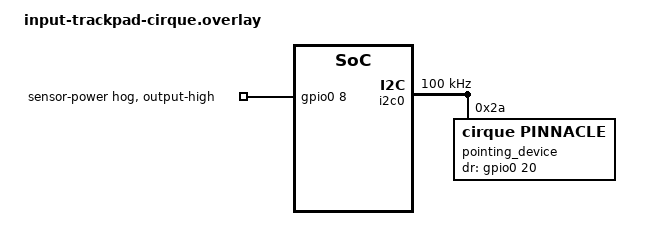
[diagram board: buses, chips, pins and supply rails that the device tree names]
/*
 * Cirque TM040040 (Pinnacle 1CA027) on the 6-pin sensor connector, in I2C
 * mode, replacing the trackball. Use instead of input-trackball.
 *
 * Connector  MCU    Function     TM040040 pad (FFC pin)
 *   1        GND    GND          GND  (11)
 *   2        P0.18  SDA          SDA  (10)
 *   3        P0.16  SCL          SCL  (9)
 *   4        P0.19  (unused)     -
 *   5        P0.20  DR (HW_DR)   DR   (4)
 *   6        VCC    VDD 3.3V     VDD  (12)
 *
 * Remove the trackpad's R1 (470k) to put it in I2C mode, and fit 4.7k
 * pull-ups on SDA/SCL (the adapter's R1/R2): the trackpad has none.
 */

#include <zephyr/dt-bindings/gpio/nordic-nrf-gpio.h>

/* Sensor power enable. The trackball driver drives P0.08 through its
 * power-gpios property; the Cirque driver has none, so hold it high from
 * boot with a GPIO hog. */
&gpio0 {
    sensor_power_hog {
        gpio-hog;
        gpios = <8 (GPIO_ACTIVE_HIGH | NRF_GPIO_DRIVE_H0H1)>;
        output-high;
        line-name = "sensor-power";
    };
};

&i2c0 {
    status = "okay";
    compatible = "nordic,nrf-twim";
    pinctrl-0 = <&i2c0_default>;   /* SDA P0.18, SCL P0.16, from the shield */
    pinctrl-1 = <&i2c0_sleep>;
    pinctrl-names = "default", "sleep";
    /* 100 kHz: the pad sits at the end of the adapter and FPC cable, and at
     * 400 kHz writes to it failed while it was being touched.
     * 100 kHz is plenty for the pad's ~110 reports/s. */
    clock-frequency = <I2C_BITRATE_STANDARD>;

    pointing_device: trackpad@2a {
        status = "okay";
        compatible = "cirque,pinnacle";
        reg = <0x2a>;
        dr-gpios = <&gpio0 20 (GPIO_ACTIVE_HIGH | GPIO_PULL_DOWN)>;
        sensitivity = "2x";

        /* Absolute position in, mouse-style motion out. The pad's own
         * relative mode is too coarse (laggy, jumpy), so the driver reads
         * the finger position at full resolution and sends the smoothed
         * change. See pinnacle_report_data_abs_rel in the driver. */
        abs-rel-divisor = <1>;
        /* ignore faint touches (hover, noise) that made the cursor float.
         * Z is touch strength 0..63. */
        absolute-mode-z-min = <3>;
        /* travel (about 45 counts/mm) before a touch starts moving the
         * cursor; raise if a resting finger still drifts */
        abs-rel-start-threshold = <8>;

        /* The pad's own tap-to-click only works in relative mode; clicks
         * come from keys. */
        no-taps;

        /* Orientation, same as the KYENS build (it inverts both axes).
         * If the cursor goes the wrong way, toggle these. */
        x-invert;
        y-invert;
    };
};
